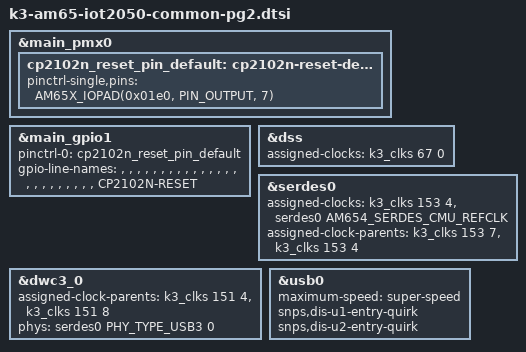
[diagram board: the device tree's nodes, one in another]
&main_pmx0 {
	cp2102n_reset_pin_default: cp2102n-reset-default-pins {
		pinctrl-single,pins = <
			AM65X_IOPAD(0x01e0, PIN_OUTPUT, 7)
		>;
	};
};
&main_gpio1 {
	pinctrl-names = "default";
	pinctrl-0 = <&cp2102n_reset_pin_default>;
	gpio-line-names =
		"", "", "", "", "", "", "", "", "", "",
		"", "", "", "", "", "", "", "", "", "",
		"", "", "", "", "CP2102N-RESET";
};
&dss {
	assigned-clocks = <&k3_clks 67 0>;
};
&serdes0 {
	assigned-clocks = <&k3_clks 153 4>, <&serdes0 AM654_SERDES_CMU_REFCLK>;
	assigned-clock-parents = <&k3_clks 153 7>, <&k3_clks 153 4>;
};
&dwc3_0 {
	assigned-clock-parents = <&k3_clks 151 4>,   
				 <&k3_clks 151 8>;   
	phys = <&serdes0 PHY_TYPE_USB3 0>;
	phy-names = "usb3-phy";
};
&usb0 {
	maximum-speed = "super-speed";
	snps,dis-u1-entry-quirk;
	snps,dis-u2-entry-quirk;
};
